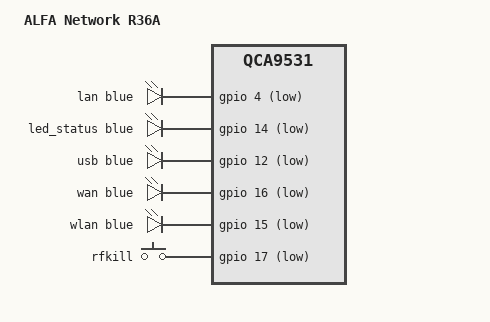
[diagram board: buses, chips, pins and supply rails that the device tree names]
// SPDX-License-Identifier: GPL-2.0-or-later OR MIT

#include <dt-bindings/leds/common.h>

#include "qca9531_alfa-network_r36a.dtsi"

/ {
	model = "ALFA Network R36A";
	compatible = "alfa-network,r36a", "qca,qca9531";

	aliases {
		led-boot = &led_status;
		led-failsafe = &led_status;
		led-running = &led_status;
		led-upgrade = &led_status;
	};

	leds {
		compatible = "gpio-leds";

		pinctrl-names = "default";
		pinctrl-0 = <&enable_gpio4 &enable_gpio16>;

		lan {
			function = LED_FUNCTION_LAN;
			color = <LED_COLOR_ID_BLUE>;
			gpios = <&gpio 4 GPIO_ACTIVE_LOW>;
		};

		led_status: status {
			function = LED_FUNCTION_STATUS;
			color = <LED_COLOR_ID_BLUE>;
			gpios = <&gpio 14 GPIO_ACTIVE_LOW>;
		};

		usb {
			function = LED_FUNCTION_USB;
			color = <LED_COLOR_ID_BLUE>;
			gpios = <&gpio 12 GPIO_ACTIVE_LOW>;
			trigger-sources = <&hub_port0>;
			linux,default-trigger = "usbport";
		};

		wan {
			function = LED_FUNCTION_WAN;
			color = <LED_COLOR_ID_BLUE>;
			gpios = <&gpio 16 GPIO_ACTIVE_LOW>;
		};

		wlan {
			function = LED_FUNCTION_WLAN;
			color = <LED_COLOR_ID_BLUE>;
			gpios = <&gpio 15 GPIO_ACTIVE_LOW>;
			linux,default-trigger = "phy0tpt";
		};
	};
};

&eth0 {
	nvmem-cells = <&macaddr_art_1002 (-2)>;
	nvmem-cell-names = "mac-address";
};

&eth1 {
	/* Workaround: keep the Ethernet interfaces order/mapping correct
	 * (GMAC0 -> eth0, GMAC1 -> eth1, same as in old ar71xx target) */
	compatible = "qca,qca9530-eth", "syscon", "simple-mfd";

	nvmem-cells = <&macaddr_art_1002 (-1)>;
	nvmem-cell-names = "mac-address";
};

&gpio_export {
	usb-power {
		gpio-export,name = "usb-power";
		gpio-export,output = <1>;
		gpios = <&gpio 3 GPIO_ACTIVE_HIGH>;
	};
};

&keys {
	rfkill {
		label = "rfkill";
		linux,code = <KEY_RFKILL>;
		gpios = <&gpio 17 GPIO_ACTIVE_LOW>;
		debounce-interval = <60>;
	};
};
